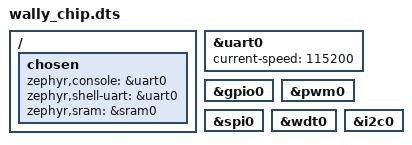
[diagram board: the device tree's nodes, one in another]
/* SPDX-License-Identifier: Apache-2.0 */

/dts-v1/;

#include <wally/wally-rv32imac.dtsi>

/ {
        chosen {
                zephyr,console = &uart0;
                zephyr,shell-uart = &uart0;
                zephyr,sram = &sram0;
        };
};

&uart0 {
        status = "okay";
        current-speed = <115200>;
};

&gpio0 {
    status = "okay";
};

&pwm0 {
    status = "okay";
};

&spi0 {
    status = "okay";
};

&wdt0 {
    status = "okay";
};

&i2c0 {
    status = "okay";
};
